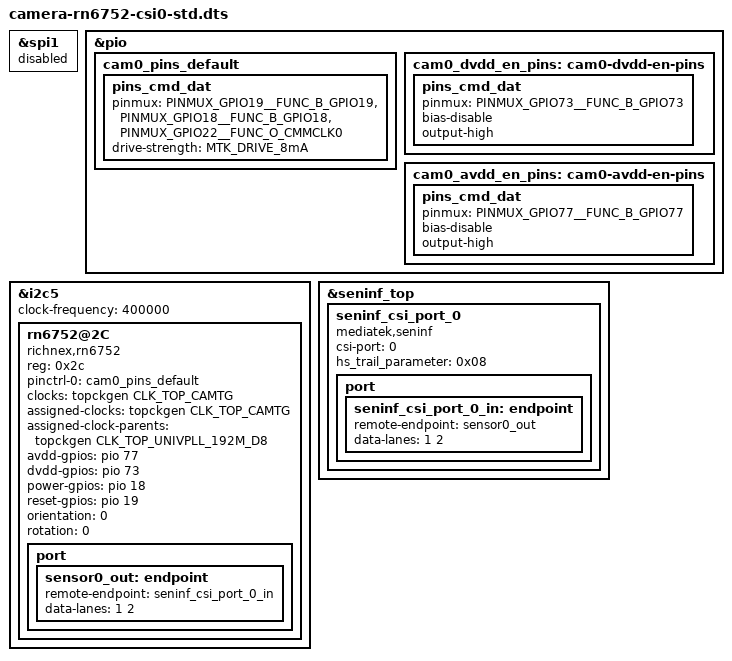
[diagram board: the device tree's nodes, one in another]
// SPDX-License-Identifier: GPL-2.0
/*
 * Copyright (c) 2023 MediaTek Inc.
 *
 */

#include <dt-bindings/clock/mediatek,mt8188-clk.h>
#include <dt-bindings/gpio/gpio.h>
#include <dt-bindings/pinctrl/mediatek,mt8188-pinfunc.h>

/dts-v1/;
/plugin/;

#include "isp71.dtsi"

/ {

	fragment@5 {
		target = <&spi1>;
		__overlay__ {
			status = "disabled";
		};
	};

	fragment@6 {
		target = <&pio>;
		__overlay__ {
			cam0_pins_default: cam0_pins_default {
				pins_cmd_dat {
					pinmux = <PINMUX_GPIO19__FUNC_B_GPIO19>,
						 <PINMUX_GPIO18__FUNC_B_GPIO18>,
						 <PINMUX_GPIO22__FUNC_O_CMMCLK0>;
					drive-strength = <MTK_DRIVE_8mA>;
				};
			};
			cam0_dvdd_en_pins: cam0-dvdd-en-pins {
				pins_cmd_dat {
					pinmux = <PINMUX_GPIO73__FUNC_B_GPIO73>;
					bias-disable;
					output-high;
				};
			};

			cam0_avdd_en_pins: cam0-avdd-en-pins {
				pins_cmd_dat {
					pinmux = <PINMUX_GPIO77__FUNC_B_GPIO77>;
					bias-disable;
					output-high;
				};
			};
		};
	};

	fragment@7 {
		target = <&i2c5>;
		__overlay__ {
			clock-frequency = <400000>;

			rn6752@2C {
				compatible = "richnex,rn6752";

				reg = <0x2c>;
				status = "okay";

				pinctrl-names = "default";
				pinctrl-0 = <&cam0_pins_default>;

				clocks = <&topckgen CLK_TOP_CAMTG>;
				assigned-clocks = <&topckgen CLK_TOP_CAMTG>;
				assigned-clock-parents = <&topckgen CLK_TOP_UNIVPLL_192M_D8>;

				avdd-gpios  = <&pio 77 GPIO_ACTIVE_HIGH>;
				dvdd-gpios  = <&pio 73 GPIO_ACTIVE_HIGH>;
				power-gpios = <&pio 18 GPIO_ACTIVE_HIGH>;
				reset-gpios = <&pio 19 GPIO_ACTIVE_HIGH>;

				orientation = <0>;
				rotation = <0>;

				port {
					sensor0_out: endpoint {
						remote-endpoint = <&seninf_csi_port_0_in>;
						data-lanes = <1 2>;
						/*link-frequencies = /bits/ 64 <480000000>;*/
					};
				};

			};
		};
	};

	fragment@8 {
		target = <&seninf_top>;
		__overlay__ {
			seninf_csi_port_0: seninf_csi_port_0 {
				compatible = "mediatek,seninf";
				csi-port = "0";
				hs_trail_parameter = <0x08>;

				port {
					seninf_csi_port_0_in: endpoint {
						remote-endpoint = <&sensor0_out>;
						data-lanes = <1 2>;
					};
				};
			};
		};
	};

};
